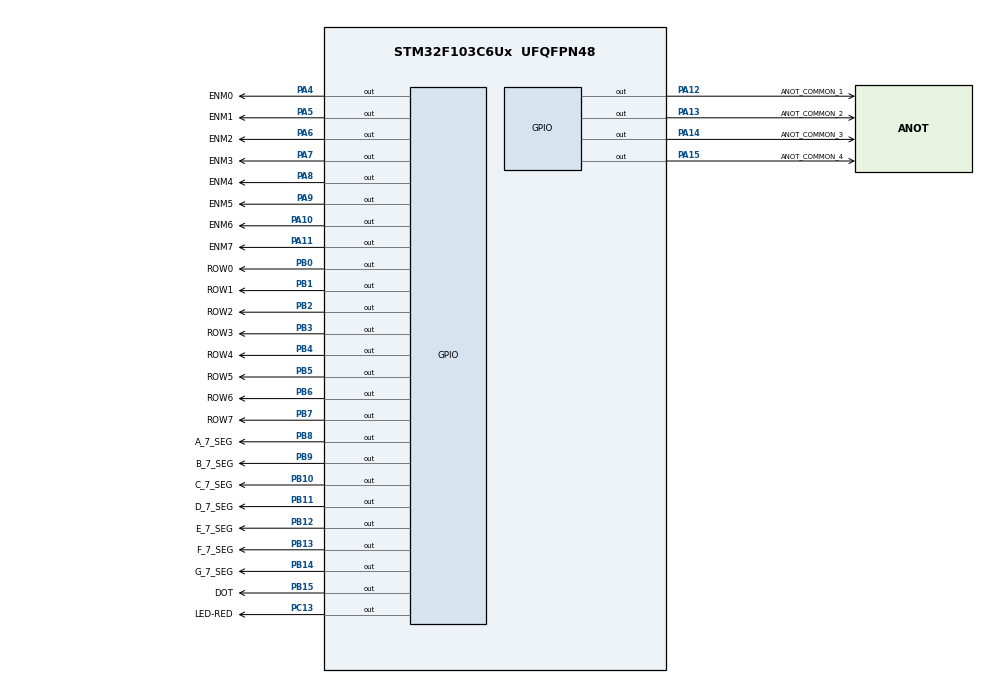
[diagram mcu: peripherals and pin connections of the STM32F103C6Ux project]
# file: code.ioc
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Mcu.Family=STM32F1
Mcu.Name=STM32F103C6Ux
Mcu.Package=UFQFPN48
NVIC.PriorityGroup=NVIC_PRIORITYGROUP_4
NVIC.TIM2_IRQn=true\:0\:0\:false\:false\:true\:true\:true
PA10.GPIO_Label=ENM6
PA10.PinState=GPIO_PIN_SET
PA10.Signal=GPIO_Output
PA11.GPIO_Label=ENM7
PA11.PinState=GPIO_PIN_SET
PA11.Signal=GPIO_Output
PA12.GPIO_Label=ANOT_COMMON_1
PA12.PinState=GPIO_PIN_SET
PA12.Signal=GPIO_Output
PA13.GPIO_Label=ANOT_COMMON_2
PA13.PinState=GPIO_PIN_SET
PA13.Signal=GPIO_Output
PA14.GPIO_Label=ANOT_COMMON_3
PA14.PinState=GPIO_PIN_SET
PA14.Signal=GPIO_Output
PA15.GPIO_Label=ANOT_COMMON_4
PA15.PinState=GPIO_PIN_SET
PA15.Signal=GPIO_Output
PA4.GPIO_Label=ENM0
PA4.PinState=GPIO_PIN_SET
PA4.Signal=GPIO_Output
PA5.GPIO_Label=ENM1
PA5.PinState=GPIO_PIN_SET
PA5.Signal=GPIO_Output
PA6.GPIO_Label=ENM2
PA6.PinState=GPIO_PIN_SET
PA6.Signal=GPIO_Output
PA7.GPIO_Label=ENM3
PA7.PinState=GPIO_PIN_SET
PA7.Signal=GPIO_Output
PA8.GPIO_Label=ENM4
PA8.PinState=GPIO_PIN_SET
PA8.Signal=GPIO_Output
PA9.GPIO_Label=ENM5
PA9.PinState=GPIO_PIN_SET
PA9.Signal=GPIO_Output
PB0.GPIO_Label=ROW0
PB0.PinState=GPIO_PIN_SET
PB0.Signal=GPIO_Output
PB1.GPIO_Label=ROW1
PB1.PinState=GPIO_PIN_SET
PB1.Signal=GPIO_Output
PB10.GPIO_Label=C_7_SEG
PB10.PinState=GPIO_PIN_SET
PB10.Signal=GPIO_Output
PB11.GPIO_Label=D_7_SEG
PB11.PinState=GPIO_PIN_SET
PB11.Signal=GPIO_Output
PB12.GPIO_Label=E_7_SEG
PB12.PinState=GPIO_PIN_SET
PB12.Signal=GPIO_Output
PB13.GPIO_Label=F_7_SEG
PB13.PinState=GPIO_PIN_SET
PB13.Signal=GPIO_Output
PB14.GPIO_Label=G_7_SEG
PB14.PinState=GPIO_PIN_SET
PB14.Signal=GPIO_Output
PB15.GPIO_Label=DOT
PB15.PinState=GPIO_PIN_SET
PB15.Signal=GPIO_Output
PB2.GPIO_Label=ROW2
PB2.PinState=GPIO_PIN_SET
PB2.Signal=GPIO_Output
PB3.GPIO_Label=ROW3
PB3.PinState=GPIO_PIN_SET
PB3.Signal=GPIO_Output
PB4.GPIO_Label=ROW4
PB4.PinState=GPIO_PIN_SET
PB4.Signal=GPIO_Output
PB5.GPIO_Label=ROW5
PB5.PinState=GPIO_PIN_SET
PB5.Signal=GPIO_Output
PB6.GPIO_Label=ROW6
PB6.PinState=GPIO_PIN_SET
PB6.Signal=GPIO_Output
PB7.GPIO_Label=ROW7
PB7.PinState=GPIO_PIN_SET
PB7.Signal=GPIO_Output
PB8.GPIO_Label=A_7_SEG
PB8.PinState=GPIO_PIN_SET
PB8.Signal=GPIO_Output
PB9.GPIO_Label=B_7_SEG
PB9.PinState=GPIO_PIN_SET
PB9.Signal=GPIO_Output
PC13-TAMPER-RTC.GPIO_Label=LED-RED
PC13-TAMPER-RTC.PinState=GPIO_PIN_SET
PC13-TAMPER-RTC.Signal=GPIO_Output
ProjectManager.HeapSize=0x200
ProjectManager.StackSize=0x400
ProjectManager.TargetToolchain=STM32CubeIDE
RCC.APB1Freq_Value=8000000
RCC.APB2Freq_Value=8000000
TIM2.Period=9
TIM2.Prescaler=7999
VP_SYS_VS_ND.Mode=No_Debug
VP_TIM2_VS_ClockSourceINT.Mode=Internal
board=custom

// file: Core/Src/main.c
/* USER CODE BEGIN Header */
/**
  ******************************************************************************
  * @file           : main.c
  * @brief          : Main program body
  ******************************************************************************
  * @attention
  *
  * <h2><center>&copy; Copyright (c) 2024 STMicroelectronics.
  * All rights reserved.</center></h2>
  *
  * This software component is licensed by ST under BSD 3-Clause license,
  * the "License"; You may not use this file except in compliance with the
  * License. You may obtain a copy of the License at:
  *                        opensource.org/licenses/BSD-3-Clause
  *
  ******************************************************************************
  */
/* USER CODE END Header */
#include "main.h"

/* USER CODE BEGIN Includes */
#include "Ex9.h"
#include "Ex1.h"
#include "Ex2.h"
#include "Ex3&4.h"
#include "Ex5.h"
/* USER CODE END Includes */

TIM_HandleTypeDef htim2;

void SystemClock_Config(void);
static void MX_GPIO_Init(void);
static void MX_TIM2_Init(void);

/* USER CODE BEGIN 0 */
	int counter = 0;
/* USER CODE END 0 */

int main(void)
{

  /* MCU Configuration--------------------------------------------------------*/

  /* Reset of all peripherals, Initializes the Flash interface and the Systick. */
  HAL_Init();

  /* Configure the system clock */
  SystemClock_Config();

  /* Initialize all configured peripherals */
  MX_GPIO_Init();
  MX_TIM2_Init();
  /* USER CODE BEGIN 2 */
	HAL_TIM_Base_Start_IT(& htim2);
//	Ex9_set();
//	Ex1_set();
//	Ex2_set();
//	Ex3_set();
	Ex5_set();
  /* USER CODE END 2 */

  /* Infinite loop */
  /* USER CODE BEGIN WHILE */
  while (1)
  {
//	  Ex9_run();
//	  Ex1_run();
//	  Ex2_run();
//	  Ex3_run();
	  Ex5_run();
    /* USER CODE END WHILE */

  }
}

void SystemClock_Config(void)
{
  RCC_OscInitTypeDef RCC_OscInitStruct = {0};
  RCC_ClkInitTypeDef RCC_ClkInitStruct = {0};

  /** Initializes the RCC Oscillators according to the specified parameters
  * in the RCC_OscInitTypeDef structure.
  */
  RCC_OscInitStruct.OscillatorType = RCC_OSCILLATORTYPE_HSI;
  RCC_OscInitStruct.HSIState = RCC_HSI_ON;
  RCC_OscInitStruct.HSICalibrationValue = RCC_HSICALIBRATION_DEFAULT;
  RCC_OscInitStruct.PLL.PLLState = RCC_PLL_NONE;
  if (HAL_RCC_OscConfig(&RCC_OscInitStruct) != HAL_OK)
  {
    Error_Handler();
  }
  /** Initializes the CPU, AHB and APB buses clocks
  */
  RCC_ClkInitStruct.ClockType = RCC_CLOCKTYPE_HCLK|RCC_CLOCKTYPE_SYSCLK
                              |RCC_CLOCKTYPE_PCLK1|RCC_CLOCKTYPE_PCLK2;
  RCC_ClkInitStruct.SYSCLKSource = RCC_SYSCLKSOURCE_HSI;
  RCC_ClkInitStruct.AHBCLKDivider = RCC_SYSCLK_DIV1;
  RCC_ClkInitStruct.APB1CLKDivider = RCC_HCLK_DIV1;
  RCC_ClkInitStruct.APB2CLKDivider = RCC_HCLK_DIV1;

  if (HAL_RCC_ClockConfig(&RCC_ClkInitStruct, FLASH_LATENCY_0) != HAL_OK)
  {
    Error_Handler();
  }
}

static void MX_TIM2_Init(void)
{

  TIM_ClockConfigTypeDef sClockSourceConfig = {0};
  TIM_MasterConfigTypeDef sMasterConfig = {0};

  htim2.Instance = TIM2;
  htim2.Init.Prescaler = 7999;
  htim2.Init.CounterMode = TIM_COUNTERMODE_UP;
  htim2.Init.Period = 9;
  htim2.Init.ClockDivision = TIM_CLOCKDIVISION_DIV1;
  htim2.Init.AutoReloadPreload = TIM_AUTORELOAD_PRELOAD_DISABLE;
  if (HAL_TIM_Base_Init(&htim2) != HAL_OK)
  {
    Error_Handler();
  }
  sClockSourceConfig.ClockSource = TIM_CLOCKSOURCE_INTERNAL;
  if (HAL_TIM_ConfigClockSource(&htim2, &sClockSourceConfig) != HAL_OK)
  {
    Error_Handler();
  }
  sMasterConfig.MasterOutputTrigger = TIM_TRGO_RESET;
  sMasterConfig.MasterSlaveMode = TIM_MASTERSLAVEMODE_DISABLE;
  if (HAL_TIMEx_MasterConfigSynchronization(&htim2, &sMasterConfig) != HAL_OK)
  {
    Error_Handler();
  }

}

static void MX_GPIO_Init(void)
{
  GPIO_InitTypeDef GPIO_InitStruct = {0};

  /* GPIO Ports Clock Enable */
  __HAL_RCC_GPIOC_CLK_ENABLE();
  __HAL_RCC_GPIOA_CLK_ENABLE();
  __HAL_RCC_GPIOB_CLK_ENABLE();

  /*Configure GPIO pin Output Level */
  HAL_GPIO_WritePin(LED_RED_GPIO_Port, LED_RED_Pin, GPIO_PIN_SET);

  /*Configure GPIO pin Output Level */
  HAL_GPIO_WritePin(GPIOA, ENM0_Pin|ENM1_Pin|ENM2_Pin|ENM3_Pin
                          |ENM4_Pin|ENM5_Pin|ENM6_Pin|ENM7_Pin
                          |ANOT_COMMON_1_Pin|ANOT_COMMON_2_Pin|ANOT_COMMON_3_Pin|ANOT_COMMON_4_Pin, GPIO_PIN_SET);

  /*Configure GPIO pin Output Level */
  HAL_GPIO_WritePin(GPIOB, ROW0_Pin|ROW1_Pin|ROW2_Pin|C_7_SEG_Pin
                          |D_7_SEG_Pin|E_7_SEG_Pin|F_7_SEG_Pin|G_7_SEG_Pin
                          |DOT_Pin|ROW3_Pin|ROW4_Pin|ROW5_Pin
                          |ROW6_Pin|ROW7_Pin|A_7_SEG_Pin|B_7_SEG_Pin, GPIO_PIN_SET);

  /*Configure GPIO pin : LED_RED_Pin */
  GPIO_InitStruct.Pin = LED_RED_Pin;
  GPIO_InitStruct.Mode = GPIO_MODE_OUTPUT_PP;
  GPIO_InitStruct.Pull = GPIO_NOPULL;
  GPIO_InitStruct.Speed = GPIO_SPEED_FREQ_LOW;
  HAL_GPIO_Init(LED_RED_GPIO_Port, &GPIO_InitStruct);

  /*Configure GPIO pins : ENM0_Pin ENM1_Pin ENM2_Pin ENM3_Pin
                           ENM4_Pin ENM5_Pin ENM6_Pin ENM7_Pin
                           ANOT_COMMON_1_Pin ANOT_COMMON_2_Pin ANOT_COMMON_3_Pin ANOT_COMMON_4_Pin */
  GPIO_InitStruct.Pin = ENM0_Pin|ENM1_Pin|ENM2_Pin|ENM3_Pin
                          |ENM4_Pin|ENM5_Pin|ENM6_Pin|ENM7_Pin
                          |ANOT_COMMON_1_Pin|ANOT_COMMON_2_Pin|ANOT_COMMON_3_Pin|ANOT_COMMON_4_Pin;
  GPIO_InitStruct.Mode = GPIO_MODE_OUTPUT_PP;
  GPIO_InitStruct.Pull = GPIO_NOPULL;
  GPIO_InitStruct.Speed = GPIO_SPEED_FREQ_LOW;
  HAL_GPIO_Init(GPIOA, &GPIO_InitStruct);

  /*Configure GPIO pins : ROW0_Pin ROW1_Pin ROW2_Pin C_7_SEG_Pin
                           D_7_SEG_Pin E_7_SEG_Pin F_7_SEG_Pin G_7_SEG_Pin
                           DOT_Pin ROW3_Pin ROW4_Pin ROW5_Pin
                           ROW6_Pin ROW7_Pin A_7_SEG_Pin B_7_SEG_Pin */
  GPIO_InitStruct.Pin = ROW0_Pin|ROW1_Pin|ROW2_Pin|C_7_SEG_Pin
                          |D_7_SEG_Pin|E_7_SEG_Pin|F_7_SEG_Pin|G_7_SEG_Pin
                          |DOT_Pin|ROW3_Pin|ROW4_Pin|ROW5_Pin
                          |ROW6_Pin|ROW7_Pin|A_7_SEG_Pin|B_7_SEG_Pin;
  GPIO_InitStruct.Mode = GPIO_MODE_OUTPUT_PP;
  GPIO_InitStruct.Pull = GPIO_NOPULL;
  GPIO_InitStruct.Speed = GPIO_SPEED_FREQ_LOW;
  HAL_GPIO_Init(GPIOB, &GPIO_InitStruct);

}

/* USER CODE BEGIN 4 */
void HAL_TIM_PeriodElapsedCallback ( TIM_HandleTypeDef * htim )
{
//	Ex9_time();
//	Ex1_time();
//	Ex2_time();
//	Ex3_time();
	Ex5_time();
}

void set_time(int time)
{
	counter = time/Tick;
}
/* USER CODE END 4 */

void Error_Handler(void)
{
  __disable_irq();
  while (1)
  {
  }
}

/************************ (C) COPYRIGHT STMicroelectronics *****END OF FILE****/
